AUTOSAR XML (schema 00045)
package /VoltageMonitor
  sender receiver interface SRI_VoltMonI_DisableCommunication
    data DE_VoltMonI_DisableCommunication: type=boolean, init-value=FALSE:0
  sender receiver interface SRI_VoltMonI_VoltState
    data DE_VoltMonI_VoltState: type=uint8
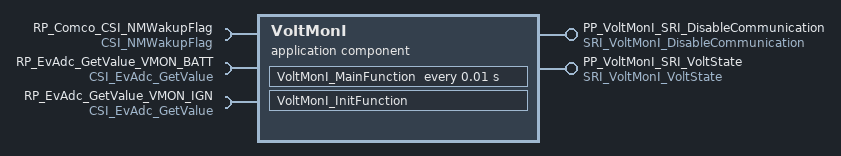
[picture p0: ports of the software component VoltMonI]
  application sw component type VoltMonI
    provide port PP_VoltMonI_SRI_DisableCommunication: provided-interface=SRI_VoltMonI_DisableCommunication
    provide port PP_VoltMonI_SRI_VoltState: provided-interface=SRI_VoltMonI_VoltState
    require port RP_Comco_CSI_NMWakupFlag: required-interface=CSI_NMWakupFlag
    require port RP_EvAdc_GetValue_VMON_BATT: required-interface=CSI_EvAdc_GetValue
    require port RP_EvAdc_GetValue_VMON_IGN: required-interface=CSI_EvAdc_GetValue
    behavior VoltageMonitor_IB: handle-termination-and-restart=NO-SUPPORT
      init event IE_VoltMonI_InitFunction: start-on-event=VoltMonI_InitFunction
      timing event TE_VoltMonI_MainFunction: start-on-event=VoltMonI_MainFunction, period=0.01
      runnable VoltMonI_InitFunction
      runnable VoltMonI_MainFunction
        data-send-points:
          access dsp_DE_VoltMonI_DisableCommu: accessed-variable=PP_VoltMonI_SRI_DisableCommunication.DE_VoltMonI_DisableCommunication
          access dsp_DE_VoltMonI_VoltState: accessed-variable=PP_VoltMonI_SRI_VoltState.DE_VoltMonI_VoltState
        sync call scp_GetPhyValue: operation=RP_EvAdc_GetValue_VMON_BATT.GetPhyValue, timeout=0.0
        sync call scp_GetPhyValue0: operation=RP_EvAdc_GetValue_VMON_IGN.GetPhyValue, timeout=0.0
        sync call scp_NMWakupFlag: operation=RP_Comco_CSI_NMWakupFlag.NMWakupFlag, timeout=0.0
  swc implementation VoltageMonitor_Impl: programming-language=C, sw-version=1.0.0, vendor-id=0, behavior=VoltageMonitor_IB
    code-descriptors:
      code CD_VoltageMonitor: artifact-descriptors=[{short-label=SWSRC, category=SWSRC}, {short-label=SWHDR, category=SWHDR}]
    resource consumption Resources
      5 x memory section:
        CODE: sw-addrmethod=CODE
        CODE_LOCAL: options=coreLocal, sw-addrmethod=CODE_LOCAL
        CONST: sw-addrmethod=CONST
        VAR_CLEARED_LOCAL: options=coreLocal, sw-addrmethod=VAR_CLEARED_LOCAL
        VAR_INIT_LOCAL: options=coreLocal, sw-addrmethod=VAR_CLEARED_LOCAL
